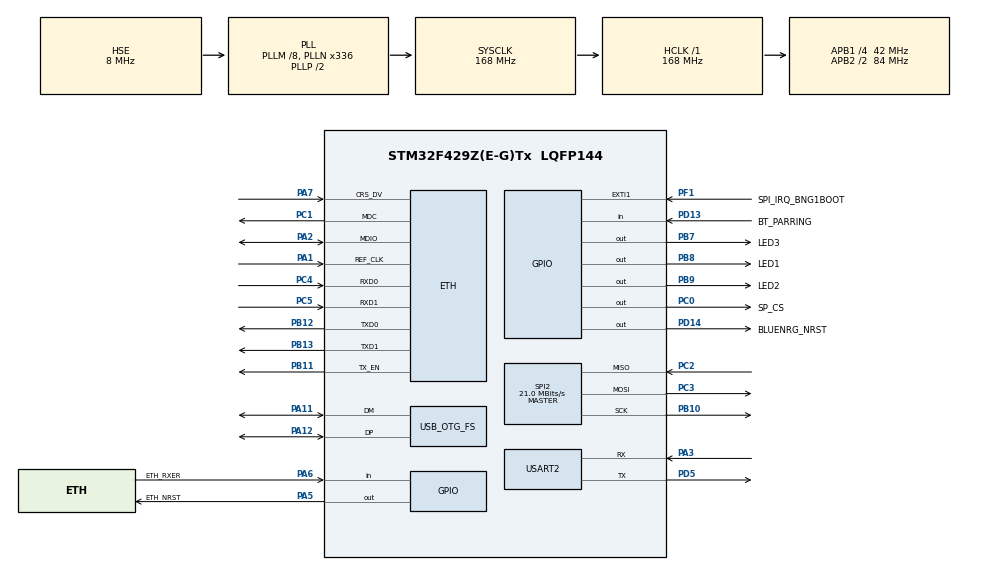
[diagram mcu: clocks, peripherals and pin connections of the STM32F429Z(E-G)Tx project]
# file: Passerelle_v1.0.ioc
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ETH.MediaInterface=HAL_ETH_RMII_MODE
Mcu.Family=STM32F4
Mcu.Name=STM32F429Z(E-G)Tx
Mcu.Package=LQFP144
NVIC.EXTI1_IRQn=true\:0\:0\:false\:false\:true\:true\:true\:true
NVIC.PriorityGroup=NVIC_PRIORITYGROUP_4
PA1.Mode=RMII
PA1.Signal=ETH_REF_CLK
PA11.Mode=Device_Only
PA11.Signal=USB_OTG_FS_DM
PA12.Mode=Device_Only
PA12.Signal=USB_OTG_FS_DP
PA13.Mode=JTAG_5_pins
PA13.Signal=SYS_JTMS-SWDIO
PA14.Mode=JTAG_5_pins
PA14.Signal=SYS_JTCK-SWCLK
PA15.Mode=JTAG_5_pins
PA15.Signal=SYS_JTDI
PA2.Mode=RMII
PA2.Signal=ETH_MDIO
PA3.Mode=Asynchronous
PA3.Signal=USART2_RX
PA5.GPIO_Label=ETH_NRST
PA5.GPIO_PuPd=GPIO_PULLUP
PA5.Signal=GPIO_Output
PA6.GPIO_Label=ETH_RXER
PA6.Signal=GPIO_Input
PA7.Mode=RMII
PA7.Signal=ETH_CRS_DV
PB10.Mode=Full_Duplex_Master
PB10.Signal=SPI2_SCK
PB11.Mode=RMII
PB11.Signal=ETH_TX_EN
PB12.Mode=RMII
PB12.Signal=ETH_TXD0
PB13.Mode=RMII
PB13.Signal=ETH_TXD1
PB3.Mode=JTAG_5_pins
PB3.Signal=SYS_JTDO-SWO
PB4.Mode=JTAG_5_pins
PB4.Signal=SYS_JTRST
PB7.GPIO_Label=LED3
PB7.Signal=GPIO_Output
PB8.GPIO_Label=LED1
PB8.Signal=GPIO_Output
PB9.GPIO_Label=LED2
PB9.Signal=GPIO_Output
PC0.GPIO_Label=SP_CS
PC0.GPIO_PuPd=GPIO_PULLDOWN
PC0.Signal=GPIO_Output
PC1.Mode=RMII
PC1.Signal=ETH_MDC
PC2.Mode=Full_Duplex_Master
PC2.Signal=SPI2_MISO
PC3.Mode=Full_Duplex_Master
PC3.Signal=SPI2_MOSI
PC4.Mode=RMII
PC4.Signal=ETH_RXD0
PC5.Mode=RMII
PC5.Signal=ETH_RXD1
PD13.GPIO_Label=BT_PARRING
PD13.Signal=GPIO_Input
PD14.GPIO_Label=BLUENRG_NRST
PD14.Signal=GPIO_Output
PD5.Mode=Asynchronous
PD5.Signal=USART2_TX
PF1.GPIO_Label=SPI_IRQ_BNG1BOOT
PF1.Signal=GPXTI1
PH0/OSC_IN.Mode=HSE-External-Oscillator
PH0/OSC_IN.Signal=RCC_OSC_IN
PH1/OSC_OUT.Mode=HSE-External-Oscillator
PH1/OSC_OUT.Signal=RCC_OSC_OUT
ProjectManager.HeapSize=0x200
ProjectManager.StackSize=0x400
ProjectManager.TargetToolchain=STM32CubeIDE
RCC.48MHZClocksFreq_Value=48000000
RCC.AHBFreq_Value=168000000
RCC.APB1CLKDivider=RCC_HCLK_DIV4
RCC.APB1Freq_Value=42000000
RCC.APB1TimFreq_Value=84000000
RCC.APB2CLKDivider=RCC_HCLK_DIV2
RCC.APB2Freq_Value=84000000
RCC.APB2TimFreq_Value=168000000
RCC.CortexFreq_Value=168000000
RCC.HCLKFreq_Value=168000000
RCC.HSE_VALUE=8000000
RCC.HSI_VALUE=16000000
RCC.LSE_VALUE=32768
RCC.PLLM=8
RCC.PLLN=336
RCC.PLLQ=7
RCC.SYSCLKFreq_VALUE=168000000
RCC.SYSCLKSource=RCC_SYSCLKSOURCE_PLLCLK
RCC.VCOOutputFreq_Value=336000000
SPI2.CalculateBaudRate=21.0 MBits/s
SPI2.Direction=SPI_DIRECTION_2LINES
SPI2.Mode=SPI_MODE_MASTER
SPI2.VirtualType=VM_MASTER
USART2.VirtualMode=VM_ASYNC
USB_OTG_FS.VirtualMode=Device_Only
VP_TIM10_VS_ClockSourceINT.Mode=Enable_Timer
VP_TIM11_VS_ClockSourceINT.Mode=Enable_Timer
board=custom

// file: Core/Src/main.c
/* USER CODE BEGIN Header */
/**
  ******************************************************************************
  * @file           : main.c
  * @brief          : Main program body
  ******************************************************************************
  * @attention
  *
  * Copyright (c) 2023 STMicroelectronics.
  * All rights reserved.
  *
  * This software is licensed under terms that can be found in the LICENSE file
  * in the root directory of this software component.
  * If no LICENSE file comes with this software, it is provided AS-IS.
  *
  ******************************************************************************
  */
/* USER CODE END Header */
#include "main.h"
#include "string.h"

ETH_TxPacketConfig TxConfig;
ETH_DMADescTypeDef  DMARxDscrTab[ETH_RX_DESC_CNT]; /* Ethernet Rx DMA Descriptors */
ETH_DMADescTypeDef  DMATxDscrTab[ETH_TX_DESC_CNT]; /* Ethernet Tx DMA Descriptors */

ETH_HandleTypeDef heth;

SPI_HandleTypeDef hspi2;

TIM_HandleTypeDef htim10;
TIM_HandleTypeDef htim11;

UART_HandleTypeDef huart2;

PCD_HandleTypeDef hpcd_USB_OTG_FS;

void SystemClock_Config(void);
static void MX_GPIO_Init(void);
static void MX_ETH_Init(void);
static void MX_TIM10_Init(void);
static void MX_TIM11_Init(void);
static void MX_USB_OTG_FS_PCD_Init(void);
static void MX_SPI2_Init(void);
static void MX_USART2_UART_Init(void);

int main(void)
{

  /* MCU Configuration--------------------------------------------------------*/

  /* Reset of all peripherals, Initializes the Flash interface and the Systick. */
  HAL_Init();

  /* Configure the system clock */
  SystemClock_Config();

  /* Initialize all configured peripherals */
  MX_GPIO_Init();
  MX_ETH_Init();
  MX_TIM10_Init();
  MX_TIM11_Init();
  MX_USB_OTG_FS_PCD_Init();
  MX_SPI2_Init();
  MX_USART2_UART_Init();

  /* Infinite loop */
  while (1)
  {

    /* USER CODE BEGIN 3 */
	  /*Allumage de la LED1*/
	  HAL_GPIO_WritePin(LED1_GPIO_Port, LED1_Pin, GPIO_PIN_SET);
	  HAL_Delay(500U);
	  HAL_GPIO_WritePin(LED1_GPIO_Port, LED1_Pin, GPIO_PIN_RESET);
	  HAL_Delay(500U);

	  /*Allumage de la LED2*/
	  HAL_GPIO_WritePin(LED2_GPIO_Port, LED2_Pin, GPIO_PIN_SET);
	  HAL_Delay(500U);
	  HAL_GPIO_WritePin(LED2_GPIO_Port, LED2_Pin, GPIO_PIN_RESET);
	  HAL_Delay(500U);

	  /*Allumage de la LED3*/
	  HAL_GPIO_WritePin(LED3_GPIO_Port, LED3_Pin, GPIO_PIN_SET);
	  HAL_Delay(500U);
	  HAL_GPIO_WritePin(LED3_GPIO_Port, LED3_Pin, GPIO_PIN_RESET);
	  HAL_Delay(500U);
  }
  /* USER CODE END 3 */
}

void SystemClock_Config(void)
{
  RCC_OscInitTypeDef RCC_OscInitStruct = {0};
  RCC_ClkInitTypeDef RCC_ClkInitStruct = {0};

  /** Configure the main internal regulator output voltage
  */
  __HAL_RCC_PWR_CLK_ENABLE();
  __HAL_PWR_VOLTAGESCALING_CONFIG(PWR_REGULATOR_VOLTAGE_SCALE1);

  /** Initializes the RCC Oscillators according to the specified parameters
  * in the RCC_OscInitTypeDef structure.
  */
  RCC_OscInitStruct.OscillatorType = RCC_OSCILLATORTYPE_HSE;
  RCC_OscInitStruct.HSEState = RCC_HSE_ON;
  RCC_OscInitStruct.PLL.PLLState = RCC_PLL_ON;
  RCC_OscInitStruct.PLL.PLLSource = RCC_PLLSOURCE_HSE;
  RCC_OscInitStruct.PLL.PLLM = 8;
  RCC_OscInitStruct.PLL.PLLN = 336;
  RCC_OscInitStruct.PLL.PLLP = RCC_PLLP_DIV2;
  RCC_OscInitStruct.PLL.PLLQ = 7;
  if (HAL_RCC_OscConfig(&RCC_OscInitStruct) != HAL_OK)
  {
    Error_Handler();
  }

  /** Initializes the CPU, AHB and APB buses clocks
  */
  RCC_ClkInitStruct.ClockType = RCC_CLOCKTYPE_HCLK|RCC_CLOCKTYPE_SYSCLK
                              |RCC_CLOCKTYPE_PCLK1|RCC_CLOCKTYPE_PCLK2;
  RCC_ClkInitStruct.SYSCLKSource = RCC_SYSCLKSOURCE_PLLCLK;
  RCC_ClkInitStruct.AHBCLKDivider = RCC_SYSCLK_DIV1;
  RCC_ClkInitStruct.APB1CLKDivider = RCC_HCLK_DIV4;
  RCC_ClkInitStruct.APB2CLKDivider = RCC_HCLK_DIV2;

  if (HAL_RCC_ClockConfig(&RCC_ClkInitStruct, FLASH_LATENCY_5) != HAL_OK)
  {
    Error_Handler();
  }
}

static void MX_ETH_Init(void)
{

   static uint8_t MACAddr[6];

  heth.Instance = ETH;
  MACAddr[0] = 0x00;
  MACAddr[1] = 0x80;
  MACAddr[2] = 0xE1;
  MACAddr[3] = 0x00;
  MACAddr[4] = 0x00;
  MACAddr[5] = 0x00;
  heth.Init.MACAddr = &MACAddr[0];
  heth.Init.MediaInterface = HAL_ETH_RMII_MODE;
  heth.Init.TxDesc = DMATxDscrTab;
  heth.Init.RxDesc = DMARxDscrTab;
  heth.Init.RxBuffLen = 1524;

  if (HAL_ETH_Init(&heth) != HAL_OK)
  {
    Error_Handler();
  }

  memset(&TxConfig, 0 , sizeof(ETH_TxPacketConfig));
  TxConfig.Attributes = ETH_TX_PACKETS_FEATURES_CSUM | ETH_TX_PACKETS_FEATURES_CRCPAD;
  TxConfig.ChecksumCtrl = ETH_CHECKSUM_IPHDR_PAYLOAD_INSERT_PHDR_CALC;
  TxConfig.CRCPadCtrl = ETH_CRC_PAD_INSERT;

}

static void MX_SPI2_Init(void)
{

  /* SPI2 parameter configuration*/
  hspi2.Instance = SPI2;
  hspi2.Init.Mode = SPI_MODE_MASTER;
  hspi2.Init.Direction = SPI_DIRECTION_2LINES;
  hspi2.Init.DataSize = SPI_DATASIZE_8BIT;
  hspi2.Init.CLKPolarity = SPI_POLARITY_LOW;
  hspi2.Init.CLKPhase = SPI_PHASE_1EDGE;
  hspi2.Init.NSS = SPI_NSS_SOFT;
  hspi2.Init.BaudRatePrescaler = SPI_BAUDRATEPRESCALER_2;
  hspi2.Init.FirstBit = SPI_FIRSTBIT_MSB;
  hspi2.Init.TIMode = SPI_TIMODE_DISABLE;
  hspi2.Init.CRCCalculation = SPI_CRCCALCULATION_DISABLE;
  hspi2.Init.CRCPolynomial = 10;
  if (HAL_SPI_Init(&hspi2) != HAL_OK)
  {
    Error_Handler();
  }

}

static void MX_TIM10_Init(void)
{

  htim10.Instance = TIM10;
  htim10.Init.Prescaler = 0;
  htim10.Init.CounterMode = TIM_COUNTERMODE_UP;
  htim10.Init.Period = 65535;
  htim10.Init.ClockDivision = TIM_CLOCKDIVISION_DIV1;
  htim10.Init.AutoReloadPreload = TIM_AUTORELOAD_PRELOAD_DISABLE;
  if (HAL_TIM_Base_Init(&htim10) != HAL_OK)
  {
    Error_Handler();
  }

}

static void MX_TIM11_Init(void)
{

  htim11.Instance = TIM11;
  htim11.Init.Prescaler = 0;
  htim11.Init.CounterMode = TIM_COUNTERMODE_UP;
  htim11.Init.Period = 65535;
  htim11.Init.ClockDivision = TIM_CLOCKDIVISION_DIV1;
  htim11.Init.AutoReloadPreload = TIM_AUTORELOAD_PRELOAD_DISABLE;
  if (HAL_TIM_Base_Init(&htim11) != HAL_OK)
  {
    Error_Handler();
  }

}

static void MX_USART2_UART_Init(void)
{

  huart2.Instance = USART2;
  huart2.Init.BaudRate = 115200;
  huart2.Init.WordLength = UART_WORDLENGTH_8B;
  huart2.Init.StopBits = UART_STOPBITS_1;
  huart2.Init.Parity = UART_PARITY_NONE;
  huart2.Init.Mode = UART_MODE_TX_RX;
  huart2.Init.HwFlowCtl = UART_HWCONTROL_NONE;
  huart2.Init.OverSampling = UART_OVERSAMPLING_16;
  if (HAL_UART_Init(&huart2) != HAL_OK)
  {
    Error_Handler();
  }

}

static void MX_USB_OTG_FS_PCD_Init(void)
{

  hpcd_USB_OTG_FS.Instance = USB_OTG_FS;
  hpcd_USB_OTG_FS.Init.dev_endpoints = 4;
  hpcd_USB_OTG_FS.Init.speed = PCD_SPEED_FULL;
  hpcd_USB_OTG_FS.Init.dma_enable = DISABLE;
  hpcd_USB_OTG_FS.Init.phy_itface = PCD_PHY_EMBEDDED;
  hpcd_USB_OTG_FS.Init.Sof_enable = DISABLE;
  hpcd_USB_OTG_FS.Init.low_power_enable = DISABLE;
  hpcd_USB_OTG_FS.Init.lpm_enable = DISABLE;
  hpcd_USB_OTG_FS.Init.vbus_sensing_enable = DISABLE;
  hpcd_USB_OTG_FS.Init.use_dedicated_ep1 = DISABLE;
  if (HAL_PCD_Init(&hpcd_USB_OTG_FS) != HAL_OK)
  {
    Error_Handler();
  }

}

static void MX_GPIO_Init(void)
{
  GPIO_InitTypeDef GPIO_InitStruct = {0};

  /* GPIO Ports Clock Enable */
  __HAL_RCC_GPIOF_CLK_ENABLE();
  __HAL_RCC_GPIOH_CLK_ENABLE();
  __HAL_RCC_GPIOC_CLK_ENABLE();
  __HAL_RCC_GPIOA_CLK_ENABLE();
  __HAL_RCC_GPIOB_CLK_ENABLE();
  __HAL_RCC_GPIOD_CLK_ENABLE();

  /*Configure GPIO pin Output Level */
  HAL_GPIO_WritePin(SP_CS_GPIO_Port, SP_CS_Pin, GPIO_PIN_RESET);

  /*Configure GPIO pin Output Level */
  HAL_GPIO_WritePin(ETH_NRST_GPIO_Port, ETH_NRST_Pin, GPIO_PIN_RESET);

  /*Configure GPIO pin Output Level */
  HAL_GPIO_WritePin(BLUENRG_NRST_GPIO_Port, BLUENRG_NRST_Pin, GPIO_PIN_RESET);

  /*Configure GPIO pin Output Level */
  HAL_GPIO_WritePin(GPIOB, LED3_Pin|LED1_Pin|LED2_Pin, GPIO_PIN_RESET);

  /*Configure GPIO pin : SPI_IRQ_BNG1BOOT_Pin */
  GPIO_InitStruct.Pin = SPI_IRQ_BNG1BOOT_Pin;
  GPIO_InitStruct.Mode = GPIO_MODE_IT_RISING;
  GPIO_InitStruct.Pull = GPIO_NOPULL;
  HAL_GPIO_Init(SPI_IRQ_BNG1BOOT_GPIO_Port, &GPIO_InitStruct);

  /*Configure GPIO pin : SP_CS_Pin */
  GPIO_InitStruct.Pin = SP_CS_Pin;
  GPIO_InitStruct.Mode = GPIO_MODE_OUTPUT_PP;
  GPIO_InitStruct.Pull = GPIO_PULLDOWN;
  GPIO_InitStruct.Speed = GPIO_SPEED_FREQ_LOW;
  HAL_GPIO_Init(SP_CS_GPIO_Port, &GPIO_InitStruct);

  /*Configure GPIO pin : ETH_NRST_Pin */
  GPIO_InitStruct.Pin = ETH_NRST_Pin;
  GPIO_InitStruct.Mode = GPIO_MODE_OUTPUT_PP;
  GPIO_InitStruct.Pull = GPIO_PULLUP;
  GPIO_InitStruct.Speed = GPIO_SPEED_FREQ_LOW;
  HAL_GPIO_Init(ETH_NRST_GPIO_Port, &GPIO_InitStruct);

  /*Configure GPIO pin : ETH_RXER_Pin */
  GPIO_InitStruct.Pin = ETH_RXER_Pin;
  GPIO_InitStruct.Mode = GPIO_MODE_INPUT;
  GPIO_InitStruct.Pull = GPIO_NOPULL;
  HAL_GPIO_Init(ETH_RXER_GPIO_Port, &GPIO_InitStruct);

  /*Configure GPIO pin : BT_PARRING_Pin */
  GPIO_InitStruct.Pin = BT_PARRING_Pin;
  GPIO_InitStruct.Mode = GPIO_MODE_INPUT;
  GPIO_InitStruct.Pull = GPIO_NOPULL;
  HAL_GPIO_Init(BT_PARRING_GPIO_Port, &GPIO_InitStruct);

  /*Configure GPIO pin : BLUENRG_NRST_Pin */
  GPIO_InitStruct.Pin = BLUENRG_NRST_Pin;
  GPIO_InitStruct.Mode = GPIO_MODE_OUTPUT_PP;
  GPIO_InitStruct.Pull = GPIO_NOPULL;
  GPIO_InitStruct.Speed = GPIO_SPEED_FREQ_LOW;
  HAL_GPIO_Init(BLUENRG_NRST_GPIO_Port, &GPIO_InitStruct);

  /*Configure GPIO pins : LED3_Pin LED1_Pin LED2_Pin */
  GPIO_InitStruct.Pin = LED3_Pin|LED1_Pin|LED2_Pin;
  GPIO_InitStruct.Mode = GPIO_MODE_OUTPUT_PP;
  GPIO_InitStruct.Pull = GPIO_NOPULL;
  GPIO_InitStruct.Speed = GPIO_SPEED_FREQ_LOW;
  HAL_GPIO_Init(GPIOB, &GPIO_InitStruct);

  /* EXTI interrupt init*/
  HAL_NVIC_SetPriority(EXTI1_IRQn, 0, 0);
  HAL_NVIC_EnableIRQ(EXTI1_IRQn);

}

void Error_Handler(void)
{
  __disable_irq();
  while (1)
  {
  }
}
